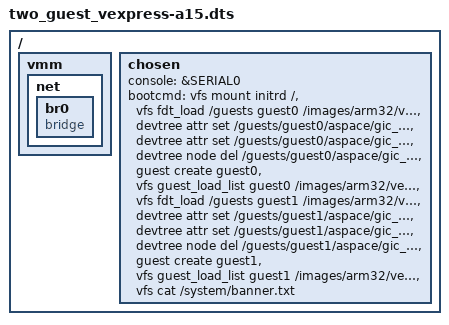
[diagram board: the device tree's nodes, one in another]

/dts-v1/;

/include/ "bcm2836-rpi-2-b.dtsi"

/ {
	vmm {
		net {
			br0 {
				device_type = "netswitch";
				compatible = "bridge";
			};
		};
	};

	chosen {
		console = &SERIAL0;
		bootcmd = /* Mount initrd device */
			  "vfs mount initrd /",

			  /* Load guest0 device tree from file */
			  "vfs fdt_load /guests guest0 /images/arm32/vexpress-a15x2.dtb mem0,physical_size,physsize,0x06000000 net0,switch,string,br0 net1,switch,string,br0",

			  /* Replace guest0 vGIC emulator with GIC emulator */
			  "devtree attr set /guests/guest0/aspace/gic_dist compatible string vexpress-v2,gic",
			  "devtree attr set /guests/guest0/aspace/gic_dist physical_size physsize 0x2000",
			  "devtree node del /guests/guest0/aspace/gic_cpu",

			  /* Create guest0 */
			  "guest create guest0",

			  /* Load guest0 images */
			  "vfs guest_load_list guest0 /images/arm32/vexpress-a15/nor_flash.list",

			  /* Load guest1 device tree from file */
			  "vfs fdt_load /guests guest1 /images/arm32/vexpress-a15x2.dtb mem0,physical_size,physsize,0x06000000 net0,switch,string,br0 net1,switch,string,br0",

			  /* Replace guest1 vGIC emulator with GIC emulator */
			  "devtree attr set /guests/guest1/aspace/gic_dist compatible string vexpress-v2,gic",
			  "devtree attr set /guests/guest1/aspace/gic_dist physical_size physsize 0x2000",
			  "devtree node del /guests/guest1/aspace/gic_cpu",

			  /* Create guest1 */
			  "guest create guest1",

			  /* Load guest1 images */
			  "vfs guest_load_list guest1 /images/arm32/vexpress-a15/nor_flash.list",

			  /* Print banner */
			  "vfs cat /system/banner.txt";
	};
};
